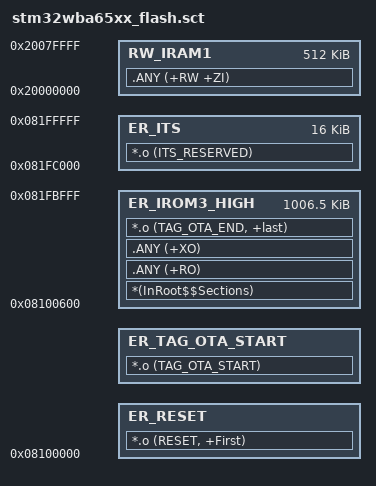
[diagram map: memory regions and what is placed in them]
; *************************************************************
; *** Scatter-Loading Description File generated by uVision ***
; *************************************************************

LR_IROM1 0x08100000 0x600 {    ; load region size_region
  ER_RESET 0x08100000 {         ; RESET section
    *.o (RESET, +First)
  }

  ER_TAG_OTA_START +0 ALIGN 0x100 {   ; put (TAG_OTA_START) at address 0x08100200 
    *.o (TAG_OTA_START)
  }
  
  RW_IRAM1 0x20000000 0x00080000  {  ; RW data
   .ANY (+RW +ZI)
  }
}

LR_IROM3 0x08100600 0x000FBA00 {
  ER_IROM3_HIGH 0x08100600 0x000FBA00 {  ; load address = execution address
	*(InRoot$$Sections)
	.ANY (+RO)
	.ANY (+XO)
	*.o (TAG_OTA_END, +last)
  }
}

LR_ITS 0x081FC000 0x4000  {  ; Separate load region for ITS
  ER_ITS 0x081FC000 0x4000  {  ; load address = execution address
   *.o (ITS_RESERVED)
  }
}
